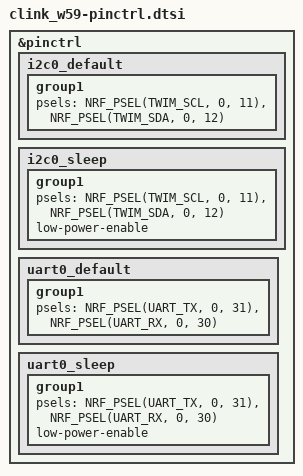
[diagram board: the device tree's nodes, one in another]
/* Pinbelegung laut KKM pca10040_W59u.h und Schaltplan K59_52832 V1.3 */

&pinctrl {
	/* LIS3DH über I2C: SCL P0.11, SDA P0.12 */
	i2c0_default: i2c0_default {
		group1 {
			psels = <NRF_PSEL(TWIM_SCL, 0, 11)>,
				<NRF_PSEL(TWIM_SDA, 0, 12)>;
		};
	};

	i2c0_sleep: i2c0_sleep {
		group1 {
			psels = <NRF_PSEL(TWIM_SCL, 0, 11)>,
				<NRF_PSEL(TWIM_SDA, 0, 12)>;
			low-power-enable;
		};
	};

	/* Testpunkte TXD (P0.31) und RXD (P0.30), nur für Debug-Ausgaben */
	uart0_default: uart0_default {
		group1 {
			psels = <NRF_PSEL(UART_TX, 0, 31)>,
				<NRF_PSEL(UART_RX, 0, 30)>;
		};
	};

	uart0_sleep: uart0_sleep {
		group1 {
			psels = <NRF_PSEL(UART_TX, 0, 31)>,
				<NRF_PSEL(UART_RX, 0, 30)>;
			low-power-enable;
		};
	};
};
